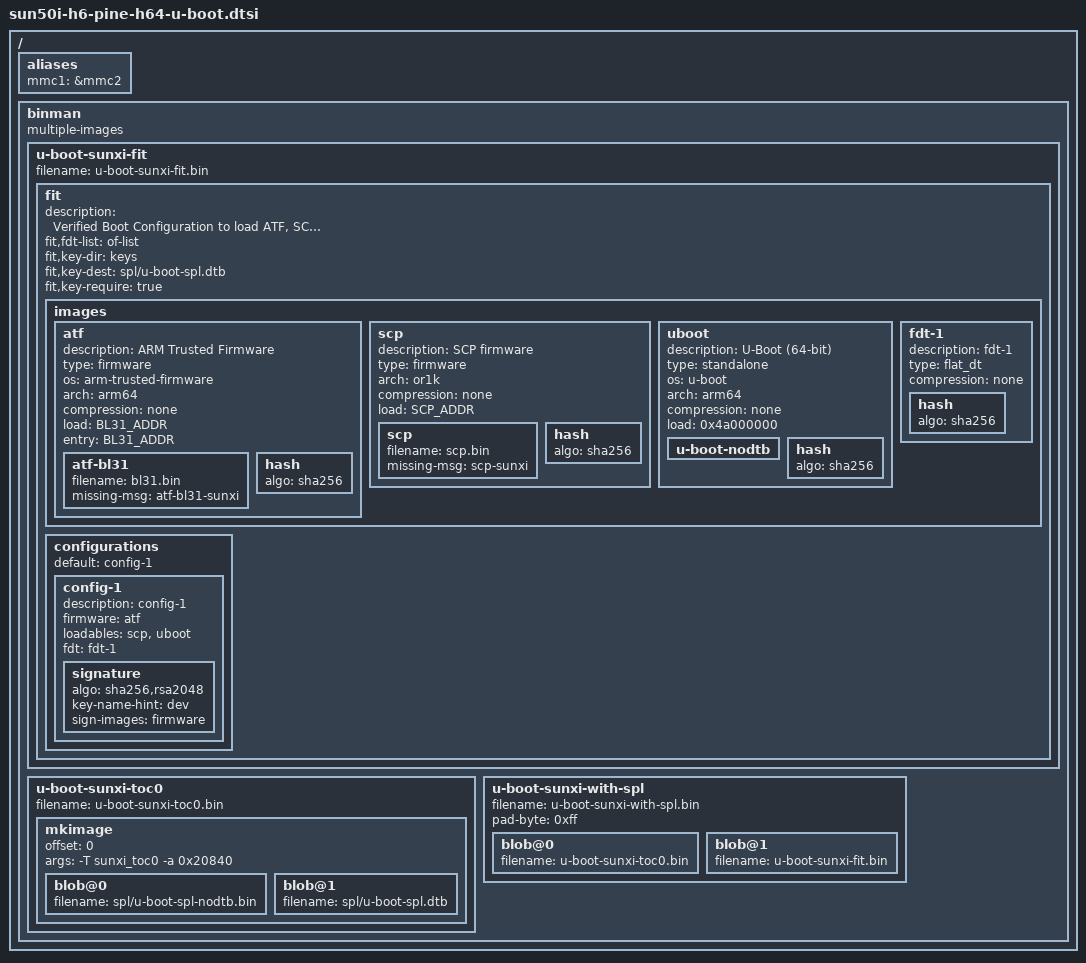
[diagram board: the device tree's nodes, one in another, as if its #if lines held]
#include <config.h>

#ifdef CONFIG_MACH_SUN50I_H6
#define BL31_ADDR 0x104000
#define  SCP_ADDR 0x114000
#else
#define BL31_ADDR  0x44000
#define  SCP_ADDR  0x50000
#endif

/ {
	aliases {
		mmc1 = &mmc2;
	};

	binman: binman {
		multiple-images;
	};
};

&binman {
    u-boot-sunxi-fit {
        filename = "u-boot-sunxi-fit.bin";

        fit {
            description = "Verified Boot Configuration to load ATF, SCP before U-Boot";
            #address-cells = <1>;
            fit,fdt-list = "of-list";

            fit,key-dir = "keys";
            fit,key-dest = "spl/u-boot-spl.dtb";
            fit,key-require = "true";

            images {
				atf {
					description = "ARM Trusted Firmware";
					type = "firmware";
					os = "arm-trusted-firmware";
					arch = "arm64";
					compression = "none";
					load = <BL31_ADDR>;
					entry = <BL31_ADDR>;

					atf-bl31 {
						filename = "bl31.bin";
						missing-msg = "atf-bl31-sunxi";
					};

                    hash {
                        algo = "sha256";
                    };

                    // Doesn't seem to work if you also add a configuration signature
//                    signature {
//                        algo = "sha256,rsa2048";
//                        key-name-hint = "dev2";
//                    };
				};

                scp {
					description = "SCP firmware";
					type = "firmware";
					arch = "or1k";
					compression = "none";
					load = <SCP_ADDR>;

					scp {
						filename = "scp.bin";
						missing-msg = "scp-sunxi";
					};

                    hash {
                        algo = "sha256";
                    };
				};


				uboot {
					description = "U-Boot (64-bit)";
					type = "standalone";
					os = "u-boot";
					arch = "arm64";
					compression = "none";
					load = <0x4a000000>;

					u-boot-nodtb {
					};

                    hash {
                        algo = "sha256";
                    };
				};

				fdt-1 {
					description = "fdt-1";
					type = "flat_dt";
					compression = "none";

                    hash {
                        algo = "sha256";
				    };
                };
            };

            configurations {
    			default = "config-1";

				config-1 {
					description = "config-1";
					firmware = "atf";
                    loadables = "scp", "uboot";
					fdt = "fdt-1";

                    signature {
                        algo = "sha256,rsa2048";
                        key-name-hint = "dev";
                        // make sure not to miss (important) things here, or you'll be in trouble
                        // sign-images = "firmware", "loadables", "fdt";
                        sign-images = "firmware";
                    };
				};
			};
        };

    };

    // After the FIT so the changes to u-boot-spl-dtb get picked up
    u-boot-sunxi-toc0 {
        filename = "u-boot-sunxi-toc0.bin";

        mkimage {
            offset = <0>;

            // TODO: figure out how to use CONFIG_SPL_TEXT_BASE
            args = "-T sunxi_toc0 -a 0x20840";

            //u-boot-spl-nodtb {};
            blob@0 {
                filename = "spl/u-boot-spl-nodtb.bin";
            };

            blob@1 {
                filename = "spl/u-boot-spl.dtb";
            };
        };
    };

	u-boot-sunxi-with-spl {
		filename = "u-boot-sunxi-with-spl.bin";
		pad-byte = <0xff>;

        blob@0 {
            filename = "u-boot-sunxi-toc0.bin";
        };

        blob@1 {
            filename = "u-boot-sunxi-fit.bin";
        };
	};
};
